# f28p65x_cpu1_dma_cla_src_sel_regs register map
Vendor: Texas Instruments
Peripheral module from a debugger description file (folder C2000).
Address unit: 16 bits
Registers are 32-bit, read-write, no defined reset value unless marked. A register's access mark holds for its fields unless they carry their own. Offsets are as the file gives them; lines under a group give offsets from that group; [hi:lo] are bit positions; {n}, {i} and the like mark numbered series; 'fields as' and 'values as' point back to an identical list; <NAME> marks a mode.

## CPU1_DMA_CLA_SRC_SEL_REGS — CPU1 DMA CLA SRC SEL Registers
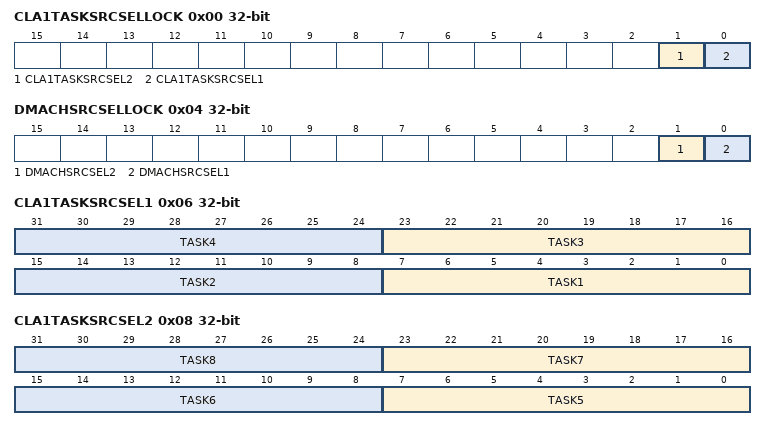
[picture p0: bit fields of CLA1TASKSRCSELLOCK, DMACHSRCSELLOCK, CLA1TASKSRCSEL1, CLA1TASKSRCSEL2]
0x00 CLA1TASKSRCSELLOCK — CLA1 Task Trigger Source Select Lock Register
  [1] CLA1TASKSRCSEL2 — CLA1TASKSRCSEL2 Register Lock bit
  [0] CLA1TASKSRCSEL1 — CLA1TASKSRCSEL1 Register Lock bit
0x04 DMACHSRCSELLOCK — DMA Channel Triger Source Select Lock Register
  [1] DMACHSRCSEL2 — DMACHSRCSEL2 Register Lock bit
  [0] DMACHSRCSEL1 — DMACHSRCSEL1 Register Lock bit
0x06 CLA1TASKSRCSEL1 — CLA1 Task Trigger Source Select Register-1
  [8n-1:8n-8] TASK{n} (n=1..4) — Selects the Trigger Source for TASK{n} of CLA1
0x08 CLA1TASKSRCSEL2 — CLA1 Task Trigger Source Select Register-2
  [8n-33:8n-40] TASK{n} (n=5..8) — Selects the Trigger Source for TASK{n} of CLA1
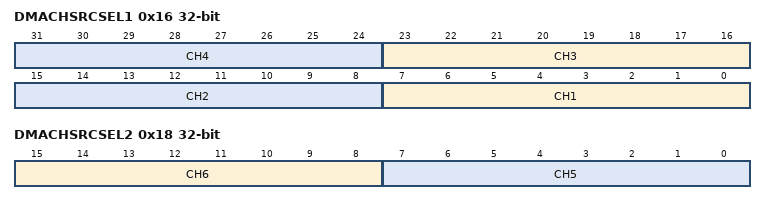
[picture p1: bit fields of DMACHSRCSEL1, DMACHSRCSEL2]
0x16 DMACHSRCSEL1 — DMA Channel Trigger Source Select Register-1
  [8n-1:8n-8] CH{n} (n=1..4) — Selects the Trigger and Sync Source CH{n} of DMA
0x18 DMACHSRCSEL2 — DMA Channel Trigger Source Select Register-2
  [15:8] CH6 — Selects the Trigger and Sync Source CH6 of DMA
  [7:0] CH5 — Selects the Trigger and Sync Source CH5 of DMA
